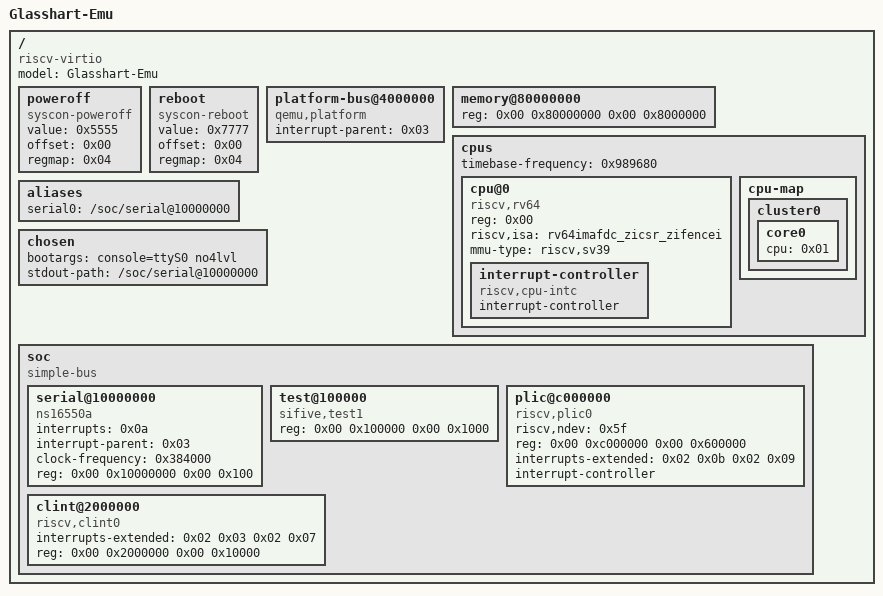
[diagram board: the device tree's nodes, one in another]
/dts-v1/;

/ {
	#address-cells = <0x02>;
	#size-cells = <0x02>;
	compatible = "riscv-virtio";
	model = "Glasshart-Emu";

	poweroff {
		value = <0x5555>;
		offset = <0x00>;
		regmap = <0x04>;
		compatible = "syscon-poweroff";
	};

	reboot {
		value = <0x7777>;
		offset = <0x00>;
		regmap = <0x04>;
		compatible = "syscon-reboot";
	};

	platform-bus@4000000 {
		interrupt-parent = <0x03>;
		ranges = <0x00 0x00 0x4000000 0x2000000>;
		#address-cells = <0x01>;
		#size-cells = <0x01>;
		compatible = "qemu,platform", "simple-bus";
	};

	memory@80000000 {
		device_type = "memory";
		reg = <0x00 0x80000000 0x00 0x8000000>;
	};

	cpus {
		#address-cells = <0x01>;
		#size-cells = <0x00>;
		timebase-frequency = <0x989680>;

		cpu@0 {
			phandle = <0x01>;
			device_type = "cpu";
			reg = <0x00>;
			status = "okay";
			compatible = "riscv,rv64";
			riscv,isa = "rv64imafdc_zicsr_zifencei";
			mmu-type = "riscv,sv39";

			interrupt-controller {
				#interrupt-cells = <0x01>;
				interrupt-controller;
				compatible = "riscv,cpu-intc";
				phandle = <0x02>;
			};
		};

		cpu-map {
			cluster0 {
				core0 {
					cpu = <0x01>;
				};
			};
		};
	};

	aliases {
		serial0 = "/soc/serial@10000000";
	};

	chosen {
		bootargs = "console=ttyS0 no4lvl";
		stdout-path = "/soc/serial@10000000";
	};

	soc {
		#address-cells = <0x02>;
		#size-cells = <0x02>;
		compatible = "simple-bus";
		ranges;

		serial@10000000 {
			interrupts = <0x0a>;
			interrupt-parent = <0x03>;
			clock-frequency = <0x384000>;
			reg = <0x00 0x10000000 0x00 0x100>;
			compatible = "ns16550a";
		};

		test@100000 {
			phandle = <0x04>;
			reg = <0x00 0x100000 0x00 0x1000>;
			compatible = "sifive,test1", "sifive,test0", "syscon";
		};

		plic@c000000 {
			phandle = <0x03>;
			riscv,ndev = <0x5f>;
			reg = <0x00 0xc000000 0x00 0x600000>;
			interrupts-extended = <0x02 0x0b 0x02 0x09>;
			interrupt-controller;
			compatible = "riscv,plic0";
			#interrupt-cells = <0x01>;
		};

		clint@2000000 {
			interrupts-extended = <0x02 0x03 0x02 0x07>;
			reg = <0x00 0x2000000 0x00 0x10000>;
			compatible = "riscv,clint0";
		};
	};
};
